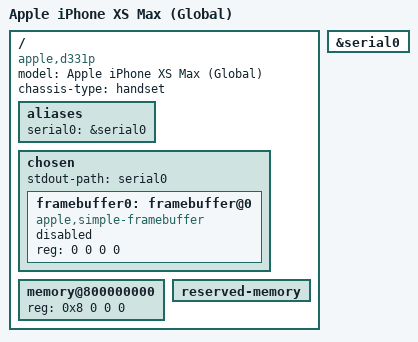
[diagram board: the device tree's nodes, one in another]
// SPDX-License-Identifier: GPL-2.0+ OR MIT
/*
 * Apple iPhone XS Max (Global), D331p, iPhone11,6
 *
 * The SoC blocks in t8020.dtsi were diffed against the D321AP (iPhone XS)
 * DeviceTree and come out identical, so only this board file differs.
 *
 * Copyright (c) 2026, kiki <kieran@lavato.net>
 */

/dts-v1/;

#include "t8020.dtsi"

/ {
	compatible = "apple,d331p", "apple,t8020", "apple,arm-platform";
	model = "Apple iPhone XS Max (Global)";
	chassis-type = "handset";

	aliases {
		serial0 = &serial0;
	};

	chosen {
		#address-cells = <2>;
		#size-cells = <2>;
		ranges;

		stdout-path = "serial0";

		/*
		 * This is the console you can actually read without a serial
		 * cable. m1n1 fills in the address and the format properties
		 * from the framebuffer iBoot already set up, then flips this to
		 * okay. There is no display driver involved, so the picture
		 * freezes as handed over.
		 *
		 * No power-domains here, unlike T8015: this tree has no pmgr
		 * node, so nothing is going to gate the display behind our back.
		 */
		framebuffer0: framebuffer@0 {
			compatible = "apple,simple-framebuffer", "simple-framebuffer";
			reg = <0 0 0 0>; /* To be filled by loader */
			status = "disabled";
		};
	};

	memory@800000000 {
		device_type = "memory";
		reg = <0x8 0 0 0>; /* To be filled by loader */
	};

	reserved-memory {
		#address-cells = <2>;
		#size-cells = <2>;
		ranges;

		/* To be filled by loader */
	};
};

&serial0 {
	status = "okay";
};
